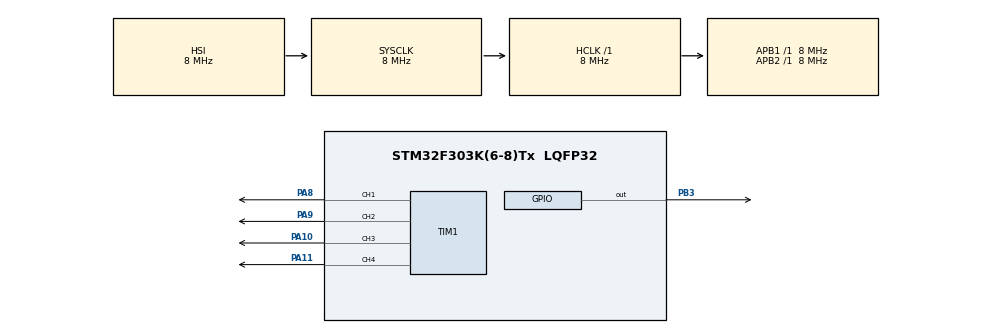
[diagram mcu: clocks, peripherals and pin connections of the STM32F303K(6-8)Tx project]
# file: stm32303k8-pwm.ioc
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Mcu.Family=STM32F3
Mcu.Name=STM32F303K(6-8)Tx
Mcu.Package=LQFP32
NVIC.PriorityGroup=NVIC_PRIORITYGROUP_4
NVIC.TIM2_IRQn=true\:0\:0\:false\:false\:true\:true\:true\:true
PA10.Signal=S_TIM1_CH3
PA11.Signal=S_TIM1_CH4
PA8.Signal=S_TIM1_CH1
PA9.Signal=S_TIM1_CH2
PB3.Signal=GPIO_Output
ProjectManager.HeapSize=0x200
ProjectManager.StackSize=0x400
ProjectManager.TargetToolchain=STM32CubeIDE
RCC.AHBFreq_Value=8000000
RCC.APB1Freq_Value=8000000
RCC.APB2Freq_Value=8000000
RCC.CortexFreq_Value=8000000
RCC.HSE_VALUE=8000000
RCC.HSI_VALUE=8000000
RCC.SYSCLKFreq_VALUE=8000000
SH.S_TIM1_CH1.0=TIM1_CH1,PWM Generation1 CH1
SH.S_TIM1_CH2.0=TIM1_CH2,PWM Generation2 CH2
SH.S_TIM1_CH3.0=TIM1_CH3,PWM Generation3 CH3
SH.S_TIM1_CH4.0=TIM1_CH4,PWM Generation4 CH4
TIM1.Channel-PWM\ Generation1\ CH1=TIM_CHANNEL_1
TIM1.Channel-PWM\ Generation2\ CH2=TIM_CHANNEL_2
TIM1.Channel-PWM\ Generation3\ CH3=TIM_CHANNEL_3
TIM1.Channel-PWM\ Generation4\ CH4=TIM_CHANNEL_4
TIM2.Period=400000
VP_TIM2_VS_ClockSourceINT.Mode=Internal
board=custom

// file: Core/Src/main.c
/* USER CODE BEGIN Header */
/**
  ******************************************************************************
  * @file           : main.c
  * @brief          : Main program body
  ******************************************************************************
  * @attention
  *
  * Copyright (c) 2026 STMicroelectronics.
  * All rights reserved.
  *
  * This software is licensed under terms that can be found in the LICENSE file
  * in the root directory of this software component.
  * If no LICENSE file comes with this software, it is provided AS-IS.
  *
  ******************************************************************************
  */
/* USER CODE END Header */
#include "main.h"

/* USER CODE BEGIN Includes */
#include "Program.h"

/* USER CODE END Includes */

TIM_HandleTypeDef htim1;
TIM_HandleTypeDef htim2;

void SystemClock_Config(void);
static void MX_GPIO_Init(void);
static void MX_TIM1_Init(void);
static void MX_TIM2_Init(void);

int main(void)
{

  /* MCU Configuration--------------------------------------------------------*/

  /* Reset of all peripherals, Initializes the Flash interface and the Systick. */
  HAL_Init();

  /* Configure the system clock */
  SystemClock_Config();

  /* Initialize all configured peripherals */
  MX_GPIO_Init();
  MX_TIM1_Init();
  MX_TIM2_Init();

  /* Infinite loop */
  while (1)
  {

    /* USER CODE BEGIN 3 */

  /* Move runtime logic into Program::Run() to minimize main.cpp user code */
  {
    Program program(&htim1, &htim2);
    program.Run();
  }
  }
  /* USER CODE END 3 */
}

void SystemClock_Config(void)
{
  RCC_OscInitTypeDef RCC_OscInitStruct = {0};
  RCC_ClkInitTypeDef RCC_ClkInitStruct = {0};
  RCC_PeriphCLKInitTypeDef PeriphClkInit = {0};

  /** Initializes the RCC Oscillators according to the specified parameters
  * in the RCC_OscInitTypeDef structure.
  */
  RCC_OscInitStruct.OscillatorType = RCC_OSCILLATORTYPE_HSI;
  RCC_OscInitStruct.HSIState = RCC_HSI_ON;
  RCC_OscInitStruct.HSICalibrationValue = RCC_HSICALIBRATION_DEFAULT;
  RCC_OscInitStruct.PLL.PLLState = RCC_PLL_NONE;
  if (HAL_RCC_OscConfig(&RCC_OscInitStruct) != HAL_OK)
  {
    Error_Handler();
  }

  /** Initializes the CPU, AHB and APB buses clocks
  */
  RCC_ClkInitStruct.ClockType = RCC_CLOCKTYPE_HCLK|RCC_CLOCKTYPE_SYSCLK
                              |RCC_CLOCKTYPE_PCLK1|RCC_CLOCKTYPE_PCLK2;
  RCC_ClkInitStruct.SYSCLKSource = RCC_SYSCLKSOURCE_HSI;
  RCC_ClkInitStruct.AHBCLKDivider = RCC_SYSCLK_DIV1;
  RCC_ClkInitStruct.APB1CLKDivider = RCC_HCLK_DIV1;
  RCC_ClkInitStruct.APB2CLKDivider = RCC_HCLK_DIV1;

  if (HAL_RCC_ClockConfig(&RCC_ClkInitStruct, FLASH_LATENCY_0) != HAL_OK)
  {
    Error_Handler();
  }
  PeriphClkInit.PeriphClockSelection = RCC_PERIPHCLK_TIM1;
  PeriphClkInit.Tim1ClockSelection = RCC_TIM1CLK_HCLK;
  if (HAL_RCCEx_PeriphCLKConfig(&PeriphClkInit) != HAL_OK)
  {
    Error_Handler();
  }
}

static void MX_TIM1_Init(void)
{

  TIM_MasterConfigTypeDef sMasterConfig = {0};
  TIM_OC_InitTypeDef sConfigOC = {0};
  TIM_BreakDeadTimeConfigTypeDef sBreakDeadTimeConfig = {0};

  htim1.Instance = TIM1;
  htim1.Init.Prescaler = 0;
  htim1.Init.CounterMode = TIM_COUNTERMODE_UP;
  htim1.Init.Period = 65535;
  htim1.Init.ClockDivision = TIM_CLOCKDIVISION_DIV1;
  htim1.Init.RepetitionCounter = 0;
  htim1.Init.AutoReloadPreload = TIM_AUTORELOAD_PRELOAD_DISABLE;
  if (HAL_TIM_PWM_Init(&htim1) != HAL_OK)
  {
    Error_Handler();
  }
  sMasterConfig.MasterOutputTrigger = TIM_TRGO_RESET;
  sMasterConfig.MasterOutputTrigger2 = TIM_TRGO2_RESET;
  sMasterConfig.MasterSlaveMode = TIM_MASTERSLAVEMODE_DISABLE;
  if (HAL_TIMEx_MasterConfigSynchronization(&htim1, &sMasterConfig) != HAL_OK)
  {
    Error_Handler();
  }
  sConfigOC.OCMode = TIM_OCMODE_PWM1;
  sConfigOC.Pulse = 0;
  sConfigOC.OCPolarity = TIM_OCPOLARITY_HIGH;
  sConfigOC.OCNPolarity = TIM_OCNPOLARITY_HIGH;
  sConfigOC.OCFastMode = TIM_OCFAST_DISABLE;
  sConfigOC.OCIdleState = TIM_OCIDLESTATE_RESET;
  sConfigOC.OCNIdleState = TIM_OCNIDLESTATE_RESET;
  if (HAL_TIM_PWM_ConfigChannel(&htim1, &sConfigOC, TIM_CHANNEL_1) != HAL_OK)
  {
    Error_Handler();
  }
  if (HAL_TIM_PWM_ConfigChannel(&htim1, &sConfigOC, TIM_CHANNEL_2) != HAL_OK)
  {
    Error_Handler();
  }
  if (HAL_TIM_PWM_ConfigChannel(&htim1, &sConfigOC, TIM_CHANNEL_3) != HAL_OK)
  {
    Error_Handler();
  }
  if (HAL_TIM_PWM_ConfigChannel(&htim1, &sConfigOC, TIM_CHANNEL_4) != HAL_OK)
  {
    Error_Handler();
  }
  sBreakDeadTimeConfig.OffStateRunMode = TIM_OSSR_DISABLE;
  sBreakDeadTimeConfig.OffStateIDLEMode = TIM_OSSI_DISABLE;
  sBreakDeadTimeConfig.LockLevel = TIM_LOCKLEVEL_OFF;
  sBreakDeadTimeConfig.DeadTime = 0;
  sBreakDeadTimeConfig.BreakState = TIM_BREAK_DISABLE;
  sBreakDeadTimeConfig.BreakPolarity = TIM_BREAKPOLARITY_HIGH;
  sBreakDeadTimeConfig.BreakFilter = 0;
  sBreakDeadTimeConfig.Break2State = TIM_BREAK2_DISABLE;
  sBreakDeadTimeConfig.Break2Polarity = TIM_BREAK2POLARITY_HIGH;
  sBreakDeadTimeConfig.Break2Filter = 0;
  sBreakDeadTimeConfig.AutomaticOutput = TIM_AUTOMATICOUTPUT_DISABLE;
  if (HAL_TIMEx_ConfigBreakDeadTime(&htim1, &sBreakDeadTimeConfig) != HAL_OK)
  {
    Error_Handler();
  }
  HAL_TIM_MspPostInit(&htim1);

}

static void MX_TIM2_Init(void)
{

  TIM_ClockConfigTypeDef sClockSourceConfig = {0};
  TIM_MasterConfigTypeDef sMasterConfig = {0};

  htim2.Instance = TIM2;
  /* Configure TIM2 to generate 1ms tick: APB1 timer clock assumed 8MHz */
  htim2.Init.Prescaler = 7999; /* 8MHz / (7999+1) = 1000 Hz */
  htim2.Init.CounterMode = TIM_COUNTERMODE_UP;
  htim2.Init.Period = 0; /* overflow each tick -> 1ms */
  htim2.Init.ClockDivision = TIM_CLOCKDIVISION_DIV1;
  htim2.Init.AutoReloadPreload = TIM_AUTORELOAD_PRELOAD_DISABLE;
  if (HAL_TIM_Base_Init(&htim2) != HAL_OK)
  {
    Error_Handler();
  }
  sClockSourceConfig.ClockSource = TIM_CLOCKSOURCE_INTERNAL;
  if (HAL_TIM_ConfigClockSource(&htim2, &sClockSourceConfig) != HAL_OK)
  {
    Error_Handler();
  }
  sMasterConfig.MasterOutputTrigger = TIM_TRGO_RESET;
  sMasterConfig.MasterSlaveMode = TIM_MASTERSLAVEMODE_DISABLE;
  if (HAL_TIMEx_MasterConfigSynchronization(&htim2, &sMasterConfig) != HAL_OK)
  {
    Error_Handler();
  }

}

static void MX_GPIO_Init(void)
{
  GPIO_InitTypeDef GPIO_InitStruct = {0};

  /* GPIO Ports Clock Enable */
  __HAL_RCC_GPIOA_CLK_ENABLE();
  __HAL_RCC_GPIOB_CLK_ENABLE();

  /*Configure GPIO pin Output Level */
  HAL_GPIO_WritePin(GPIOB, GPIO_PIN_3, GPIO_PIN_RESET);

  /*Configure GPIO pin : PB3 */
  GPIO_InitStruct.Pin = GPIO_PIN_3;
  GPIO_InitStruct.Mode = GPIO_MODE_OUTPUT_PP;
  GPIO_InitStruct.Pull = GPIO_NOPULL;
  GPIO_InitStruct.Speed = GPIO_SPEED_FREQ_LOW;
  HAL_GPIO_Init(GPIOB, &GPIO_InitStruct);

}

void Error_Handler(void)
{
  __disable_irq();
  while (1)
  {
  }
}
